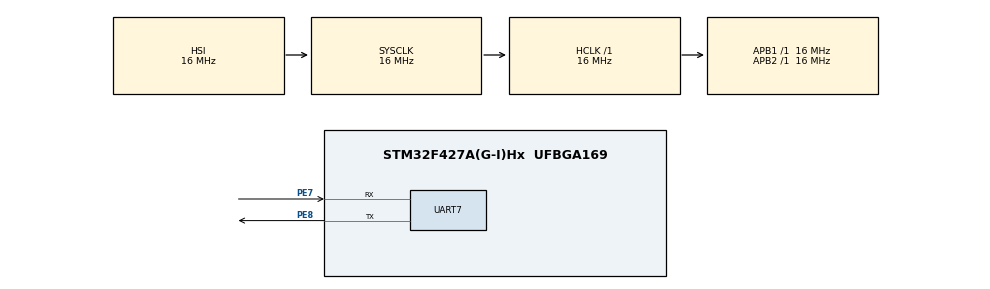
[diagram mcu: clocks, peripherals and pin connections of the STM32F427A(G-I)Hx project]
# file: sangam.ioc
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FREERTOS.Tasks01=defaultTask,24,128,StartDefaultTask,Default,NULL,Dynamic,NULL,NULL
Mcu.Family=STM32F4
Mcu.Name=STM32F427A(G-I)Hx
Mcu.Package=UFBGA169
NVIC.PriorityGroup=NVIC_PRIORITYGROUP_4
NVIC.TIM1_BRK_TIM9_IRQn=true\:15\:0\:false\:false\:true\:false\:false\:true
NVIC.TimeBase=TIM1_BRK_TIM9_IRQn
NVIC.TimeBaseIP=TIM9
PA13.Mode=Serial_Wire
PA13.Signal=SYS_JTMS-SWDIO
PA14.Mode=Serial_Wire
PA14.Signal=SYS_JTCK-SWCLK
PE7.Mode=Asynchronous
PE7.Signal=UART7_RX
PE8.Mode=Asynchronous
PE8.Signal=UART7_TX
ProjectManager.HeapSize=0x200
ProjectManager.StackSize=0x400
ProjectManager.TargetToolchain=STM32CubeIDE
RCC.AHBFreq_Value=16000000
RCC.APB1Freq_Value=16000000
RCC.APB2Freq_Value=16000000
RCC.CortexFreq_Value=16000000
RCC.HSE_VALUE=25000000
RCC.HSI_VALUE=16000000
RCC.LSE_VALUE=32768
RCC.SYSCLKFreq_VALUE=16000000
RCC.VCOOutputFreq_Value=192000000
UART7.VirtualMode=Asynchronous
VP_FREERTOS_VS_CMSIS_V2.Mode=CMSIS_V2
VP_SYS_VS_tim9.Mode=TIM9
board=custom

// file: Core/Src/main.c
/* USER CODE BEGIN Header */
/**
  ******************************************************************************
  * @file           : main.c
  * @brief          : Main program body
  ******************************************************************************
  * @attention
  *
  * <h2><center>&copy; Copyright (c) 2024 STMicroelectronics.
  * All rights reserved.</center></h2>
  *
  * This software component is licensed by ST under BSD 3-Clause license,
  * the "License"; You may not use this file except in compliance with the
  * License. You may obtain a copy of the License at:
  *                        opensource.org/licenses/BSD-3-Clause
  *
  ******************************************************************************
  */
/* USER CODE END Header */
#include "main.h"
#include "cmsis_os.h"

UART_HandleTypeDef huart7;

/* Definitions for defaultTask */
osThreadId_t defaultTaskHandle;
const osThreadAttr_t defaultTask_attributes = {
  .name = "defaultTask",
  .stack_size = 128 * 4,
  .priority = (osPriority_t) osPriorityNormal,
};

void SystemClock_Config(void);
static void MX_GPIO_Init(void);
static void MX_UART7_Init(void);
void StartDefaultTask(void *argument);

int main(void)
{

  /* MCU Configuration--------------------------------------------------------*/

  /* Reset of all peripherals, Initializes the Flash interface and the Systick. */
  HAL_Init();

  /* Configure the system clock */
  SystemClock_Config();

  /* Initialize all configured peripherals */
  MX_GPIO_Init();
  MX_UART7_Init();

  /* Init scheduler */
  osKernelInitialize();

  /* Create the thread(s) */
  /* creation of defaultTask */
  defaultTaskHandle = osThreadNew(StartDefaultTask, NULL, &defaultTask_attributes);

  /* Start scheduler */
  osKernelStart();

  /* We should never get here as control is now taken by the scheduler */
  /* Infinite loop */
  while (1)
  {

  }
}

void SystemClock_Config(void)
{
  RCC_OscInitTypeDef RCC_OscInitStruct = {0};
  RCC_ClkInitTypeDef RCC_ClkInitStruct = {0};

  /** Configure the main internal regulator output voltage
  */
  __HAL_RCC_PWR_CLK_ENABLE();
  __HAL_PWR_VOLTAGESCALING_CONFIG(PWR_REGULATOR_VOLTAGE_SCALE3);
  /** Initializes the RCC Oscillators according to the specified parameters
  * in the RCC_OscInitTypeDef structure.
  */
  RCC_OscInitStruct.OscillatorType = RCC_OSCILLATORTYPE_HSI;
  RCC_OscInitStruct.HSIState = RCC_HSI_ON;
  RCC_OscInitStruct.HSICalibrationValue = RCC_HSICALIBRATION_DEFAULT;
  RCC_OscInitStruct.PLL.PLLState = RCC_PLL_NONE;
  if (HAL_RCC_OscConfig(&RCC_OscInitStruct) != HAL_OK)
  {
    Error_Handler();
  }
  /** Initializes the CPU, AHB and APB buses clocks
  */
  RCC_ClkInitStruct.ClockType = RCC_CLOCKTYPE_HCLK|RCC_CLOCKTYPE_SYSCLK
                              |RCC_CLOCKTYPE_PCLK1|RCC_CLOCKTYPE_PCLK2;
  RCC_ClkInitStruct.SYSCLKSource = RCC_SYSCLKSOURCE_HSI;
  RCC_ClkInitStruct.AHBCLKDivider = RCC_SYSCLK_DIV1;
  RCC_ClkInitStruct.APB1CLKDivider = RCC_HCLK_DIV1;
  RCC_ClkInitStruct.APB2CLKDivider = RCC_HCLK_DIV1;

  if (HAL_RCC_ClockConfig(&RCC_ClkInitStruct, FLASH_LATENCY_0) != HAL_OK)
  {
    Error_Handler();
  }
}

static void MX_UART7_Init(void)
{

  huart7.Instance = UART7;
  huart7.Init.BaudRate = 115200;
  huart7.Init.WordLength = UART_WORDLENGTH_8B;
  huart7.Init.StopBits = UART_STOPBITS_1;
  huart7.Init.Parity = UART_PARITY_NONE;
  huart7.Init.Mode = UART_MODE_TX_RX;
  huart7.Init.HwFlowCtl = UART_HWCONTROL_NONE;
  huart7.Init.OverSampling = UART_OVERSAMPLING_16;
  if (HAL_UART_Init(&huart7) != HAL_OK)
  {
    Error_Handler();
  }

}

static void MX_GPIO_Init(void)
{

  /* GPIO Ports Clock Enable */
  __HAL_RCC_GPIOA_CLK_ENABLE();
  __HAL_RCC_GPIOE_CLK_ENABLE();

}

void StartDefaultTask(void *argument)
{
  /* USER CODE BEGIN 5 */
  /* Infinite loop */
  for(;;)
  {HAL_UART_Transmit(&huart7,"test",1,1000);
    osDelay(1);
  }
  /* USER CODE END 5 */
}

void HAL_TIM_PeriodElapsedCallback(TIM_HandleTypeDef *htim)
{
  if (htim->Instance == TIM9) {
    HAL_IncTick();
  }
}

void Error_Handler(void)
{
  __disable_irq();
  while (1)
  {
  }
}

/************************ (C) COPYRIGHT STMicroelectronics *****END OF FILE****/
